AUTOSAR XML (schema 00048)
package /HuaweiMDC/PlatformApplication/RadarCenterApplication/Execution
  executable radar_a_cm
    root sw component prototype radar_a_cm: application-type=radar_a_cm
package /HuaweiMDC/PlatformApplication/RadarCenterApplication/SwComponent
  composition sw component type diag_test_cpp
    component diag_agent: type=diag_agent
    component radar_a_cm: type=radar_a_cm
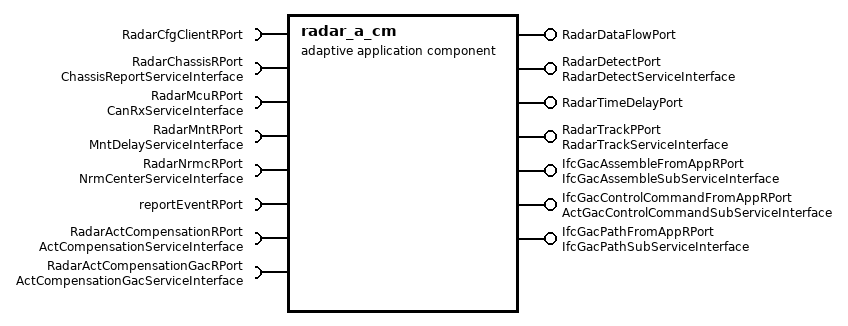
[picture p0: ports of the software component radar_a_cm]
  adaptive application sw component type radar_a_cm
    require port RadarCfgClientRPort
    require port RadarChassisRPort: required-interface=ChassisReportServiceInterface
    provide port RadarDataFlowPort
    provide port RadarDetectPort: provided-interface=RadarDetectServiceInterface
    require port RadarMcuRPort: required-interface=CanRxServiceInterface
    require port RadarMntRPort: required-interface=MntDelayServiceInterface
    require port RadarNrmcRPort: required-interface=NrmCenterServiceInterface
    provide port RadarTimeDelayPort
    provide port RadarTrackPPort: provided-interface=RadarTrackServiceInterface
    require port reportEventRPort
    require port RadarActCompensationRPort: required-interface=ActCompensationServiceInterface
    require port RadarActCompensationGacRPort: required-interface=ActCompensationGacServiceInterface
    provide port IfcGacAssembleFromAppRPort: provided-interface=IfcGacAssembleSubServiceInterface
    provide port IfcGacControlCommandFromAppRPort: provided-interface=ActGacControlCommandSubServiceInterface
    provide port IfcGacPathFromAppRPort: provided-interface=IfcGacPathSubServiceInterface
